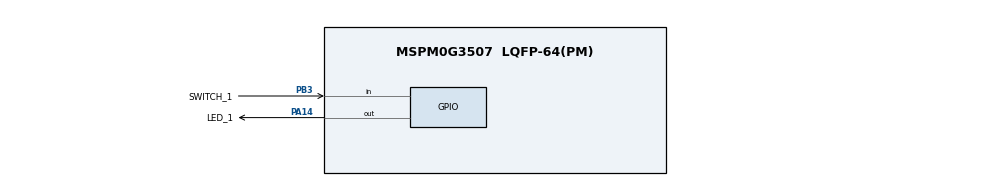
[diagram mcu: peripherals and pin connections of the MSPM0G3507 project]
/**
 * These arguments were used when this file was generated. They will be automatically applied on subsequent loads
 * via the GUI or CLI. Run CLI with '--help' for additional information on how to override these arguments.
 * @cliArgs --device "MSPM0G350X" --part "Default" --package "LQFP-64(PM)" --product "mspm0_sdk@2.10.00.04"
 * @v2CliArgs --device "MSPM0G3507" --package "LQFP-64(PM)" --product "mspm0_sdk@2.10.00.04"
 * @versions {"tool":"1.26.2+4477"}
 */

/**
 * Import the modules used in this configuration.
 */
const GPIO          = scripting.addModule("/ti/driverlib/GPIO", {}, false);
const GPIO1         = GPIO.addInstance();
const GPIO2         = GPIO.addInstance();
const SYSCTL        = scripting.addModule("/ti/driverlib/SYSCTL");
const ProjectConfig = scripting.addModule("/ti/project_config/ProjectConfig");

/**
 * Write custom configuration values to the imported modules.
 */
GPIO1.$name                              = "GPIO_SWITCH";
GPIO1.associatedPins[0].$name            = "SWITCH_1";
GPIO1.associatedPins[0].internalResistor = "PULL_UP";
GPIO1.associatedPins[0].direction        = "INPUT";
GPIO1.associatedPins[0].pin.$assign      = "PB3";

const Board = scripting.addModule("/ti/driverlib/Board", {}, false);

GPIO2.$name                         = "GPIO_LED";
GPIO2.associatedPins[0].$name       = "LED_1";
GPIO2.associatedPins[0].pin.$assign = "PA14";

SYSCTL.forceDefaultClkConfig = true;

ProjectConfig.genLibDrivers = true;
ProjectConfig.genLibCMSIS   = true;

/**
 * Pinmux solution for unlocked pins/peripherals. This ensures that minor changes to the automatic solver in a future
 * version of the tool will not impact the pinmux you originally saw.  These lines can be completely deleted in order to
 * re-solve from scratch.
 */
Board.peripheral.$suggestSolution          = "DEBUGSS";
Board.peripheral.swclkPin.$suggestSolution = "PA20";
Board.peripheral.swdioPin.$suggestSolution = "PA19";
SYSCTL.peripheral.$suggestSolution         = "SYSCTL";
